AUTOSAR XML (schema 4-0-3)
package /ComponentTypes
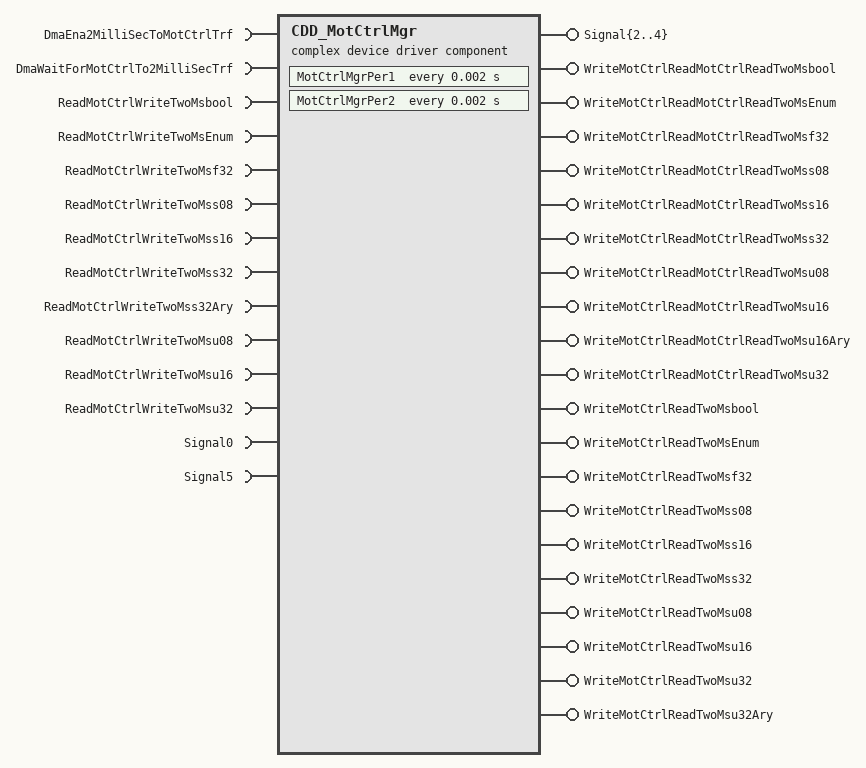
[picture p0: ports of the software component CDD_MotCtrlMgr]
  complex device driver sw component type CDD_MotCtrlMgr
    23 x provide port:
      Signal{2..4}: nonqueued-sender-com-spec{data-element=Val, init-value=-128}, provided-interface=Signal{2..4}
      WriteMotCtrlReadMotCtrlReadTwoMsbool: nonqueued-sender-com-spec{data-element=Logl, init-value=0}, provided-interface=WriteMotCtrlReadMotCtrlReadTwoMsbool
      WriteMotCtrlReadMotCtrlReadTwoMsEnum: nonqueued-sender-com-spec{data-element=Val, init-value=65535}, provided-interface=WriteMotCtrlReadMotCtrlReadTwoMsEnum
      WriteMotCtrlReadMotCtrlReadTwoMsf32: nonqueued-sender-com-spec{data-element=Val, init-value=1.0}, provided-interface=WriteMotCtrlReadMotCtrlReadTwoMsf32
      WriteMotCtrlReadMotCtrlReadTwoMss08: nonqueued-sender-com-spec{data-element=Val, init-value=-128}, provided-interface=WriteMotCtrlReadMotCtrlReadTwoMss08
      WriteMotCtrlReadMotCtrlReadTwoMss16: nonqueued-sender-com-spec{data-element=Val, init-value=-32768}, provided-interface=WriteMotCtrlReadMotCtrlReadTwoMss16
      WriteMotCtrlReadMotCtrlReadTwoMss32: nonqueued-sender-com-spec{data-element=Val, init-value=-2147483647}, provided-interface=WriteMotCtrlReadMotCtrlReadTwoMss32
      WriteMotCtrlReadMotCtrlReadTwoMsu08: nonqueued-sender-com-spec{data-element=Val, init-value=255}, provided-interface=WriteMotCtrlReadMotCtrlReadTwoMsu08
      WriteMotCtrlReadMotCtrlReadTwoMsu16: nonqueued-sender-com-spec{data-element=Val, init-value=65535}, provided-interface=WriteMotCtrlReadMotCtrlReadTwoMsu16
      WriteMotCtrlReadMotCtrlReadTwoMsu16Ary: nonqueued-sender-com-spec{data-element=Ary1D, init-value=[0, 65535]}, provided-interface=WriteMotCtrlReadMotCtrlReadTwoMsu16Ary
      WriteMotCtrlReadMotCtrlReadTwoMsu32: nonqueued-sender-com-spec{data-element=Val, init-value=4294967295}, provided-interface=WriteMotCtrlReadMotCtrlReadTwoMsu32
      WriteMotCtrlReadTwoMsbool: nonqueued-sender-com-spec{data-element=Logl, init-value=1}, provided-interface=WriteMotCtrlReadTwoMsbool
      WriteMotCtrlReadTwoMsEnum: nonqueued-sender-com-spec{data-element=Val, init-value=65535}, provided-interface=WriteMotCtrlReadTwoMsEnum
      WriteMotCtrlReadTwoMsf32: nonqueued-sender-com-spec{data-element=Val, init-value=1.0}, provided-interface=WriteMotCtrlReadTwoMsf32
      WriteMotCtrlReadTwoMss08: nonqueued-sender-com-spec{data-element=Val, init-value=-128}, provided-interface=WriteMotCtrlReadTwoMss08
      WriteMotCtrlReadTwoMss16: nonqueued-sender-com-spec{data-element=Val, init-value=-32768}, provided-interface=WriteMotCtrlReadTwoMss16
      WriteMotCtrlReadTwoMss32: nonqueued-sender-com-spec{data-element=Val, init-value=-2147483647}, provided-interface=WriteMotCtrlReadTwoMss32
      WriteMotCtrlReadTwoMsu08: nonqueued-sender-com-spec{data-element=Val, init-value=255}, provided-interface=WriteMotCtrlReadTwoMsu08
      WriteMotCtrlReadTwoMsu16: nonqueued-sender-com-spec{data-element=Val, init-value=65535}, provided-interface=WriteMotCtrlReadTwoMsu16
      WriteMotCtrlReadTwoMsu32: nonqueued-sender-com-spec{data-element=Val, init-value=4294967295}, provided-interface=WriteMotCtrlReadTwoMsu32
      WriteMotCtrlReadTwoMsu32Ary: nonqueued-sender-com-spec{data-element=Ary1D, init-value=[0, 4294967295]}, provided-interface=WriteMotCtrlReadTwoMsu32Ary
    14 x require port:
      DmaEna2MilliSecToMotCtrlTrf: required-interface=DmaEna2MilliSecToMotCtrlTrf
      DmaWaitForMotCtrlTo2MilliSecTrf: required-interface=DmaWaitForMotCtrlTo2MilliSecTrf
      ReadMotCtrlWriteTwoMsbool: nonqueued-receiver-com-spec{data-element=Logl, filter=data-filter-type=ALWAYS, init-value=0}, required-interface=ReadMotCtrlWriteTwoMsbool
      ReadMotCtrlWriteTwoMsEnum: nonqueued-receiver-com-spec{data-element=Val, filter=data-filter-type=ALWAYS, init-value=4294967295}, required-interface=ReadMotCtrlWriteTwoMsEnum
      ReadMotCtrlWriteTwoMsf32: nonqueued-receiver-com-spec{data-element=Val, filter=data-filter-type=ALWAYS, init-value=1.0}, required-interface=ReadMotCtrlWriteTwoMsf32
      ReadMotCtrlWriteTwoMss08: nonqueued-receiver-com-spec{data-element=Val, filter=data-filter-type=ALWAYS, init-value=-128}, required-interface=ReadMotCtrlWriteTwoMss08
      ReadMotCtrlWriteTwoMss16: nonqueued-receiver-com-spec{data-element=Val, filter=data-filter-type=ALWAYS, init-value=-32768}, required-interface=ReadMotCtrlWriteTwoMss16
      ReadMotCtrlWriteTwoMss32: nonqueued-receiver-com-spec{data-element=Val, filter=data-filter-type=ALWAYS, init-value=-2147483647}, required-interface=ReadMotCtrlWriteTwoMss32
      ReadMotCtrlWriteTwoMss32Ary: nonqueued-receiver-com-spec{data-element=Ary1D, filter=data-filter-type=ALWAYS, init-value=[-2147483647, 2147483647]}, required-interface=ReadMotCtrlWriteTwoMss32Ary
      ReadMotCtrlWriteTwoMsu08: nonqueued-receiver-com-spec{data-element=Val, filter=data-filter-type=ALWAYS, init-value=255}, required-interface=ReadMotCtrlWriteTwoMsu08
      ReadMotCtrlWriteTwoMsu16: nonqueued-receiver-com-spec{data-element=Val, filter=data-filter-type=ALWAYS, init-value=65535}, required-interface=ReadMotCtrlWriteTwoMsu16
      ReadMotCtrlWriteTwoMsu32: nonqueued-receiver-com-spec{data-element=Val, filter=data-filter-type=ALWAYS, init-value=4294967295}, required-interface=ReadMotCtrlWriteTwoMsu32
      Signal0: nonqueued-receiver-com-spec{data-element=Logl, filter=data-filter-type=ALWAYS, init-value=0}, required-interface=Signal0
      Signal5: nonqueued-receiver-com-spec{data-element=Logl, filter=data-filter-type=ALWAYS, init-value=0}, required-interface=Signal5
    behavior CDD_MotCtrlMgr_InternalBehavior
      timing event TMT_MotCtrlMgrPer1: start-on-event=MotCtrlMgrPer1, period=0.002
      timing event TMT_MotCtrlMgrPer2: start-on-event=MotCtrlMgrPer2, period=0.002
      runnable MotCtrlMgrPer1
        data-send-points:
          23 x access:
            SEND_Signal{2..4}_Val: accessed-variable=Signal{2..4}.Val
            SEND_WriteMotCtrlReadMotCtrlReadTwoMsbool_Logl: accessed-variable=WriteMotCtrlReadMotCtrlReadTwoMsbool.Logl
            SEND_WriteMotCtrlReadMotCtrlReadTwoMsEnum_Val: accessed-variable=WriteMotCtrlReadMotCtrlReadTwoMsEnum.Val
            SEND_WriteMotCtrlReadMotCtrlReadTwoMsf32_Val: accessed-variable=WriteMotCtrlReadMotCtrlReadTwoMsf32.Val
            SEND_WriteMotCtrlReadMotCtrlReadTwoMss08_Val: accessed-variable=WriteMotCtrlReadMotCtrlReadTwoMss08.Val
            SEND_WriteMotCtrlReadMotCtrlReadTwoMss16_Val: accessed-variable=WriteMotCtrlReadMotCtrlReadTwoMss16.Val
            SEND_WriteMotCtrlReadMotCtrlReadTwoMss32_Val: accessed-variable=WriteMotCtrlReadMotCtrlReadTwoMss32.Val
            SEND_WriteMotCtrlReadMotCtrlReadTwoMsu08_Val: accessed-variable=WriteMotCtrlReadMotCtrlReadTwoMsu08.Val
            SEND_WriteMotCtrlReadMotCtrlReadTwoMsu16_Val: accessed-variable=WriteMotCtrlReadMotCtrlReadTwoMsu16.Val
            SEND_WriteMotCtrlReadMotCtrlReadTwoMsu16Ary_Ary1D: accessed-variable=WriteMotCtrlReadMotCtrlReadTwoMsu16Ary.Ary1D
            SEND_WriteMotCtrlReadMotCtrlReadTwoMsu32_Val: accessed-variable=WriteMotCtrlReadMotCtrlReadTwoMsu32.Val
            SEND_WriteMotCtrlReadTwoMsbool_Logl: accessed-variable=WriteMotCtrlReadTwoMsbool.Logl
            SEND_WriteMotCtrlReadTwoMsEnum_Val: accessed-variable=WriteMotCtrlReadTwoMsEnum.Val
            SEND_WriteMotCtrlReadTwoMsf32_Val: accessed-variable=WriteMotCtrlReadTwoMsf32.Val
            SEND_WriteMotCtrlReadTwoMss08_Val: accessed-variable=WriteMotCtrlReadTwoMss08.Val
            SEND_WriteMotCtrlReadTwoMss16_Val: accessed-variable=WriteMotCtrlReadTwoMss16.Val
            SEND_WriteMotCtrlReadTwoMss32_Val: accessed-variable=WriteMotCtrlReadTwoMss32.Val
            SEND_WriteMotCtrlReadTwoMsu08_Val: accessed-variable=WriteMotCtrlReadTwoMsu08.Val
            SEND_WriteMotCtrlReadTwoMsu16_Val: accessed-variable=WriteMotCtrlReadTwoMsu16.Val
            SEND_WriteMotCtrlReadTwoMsu32_Val: accessed-variable=WriteMotCtrlReadTwoMsu32.Val
            SEND_WriteMotCtrlReadTwoMsu32Ary_Ary1D: accessed-variable=WriteMotCtrlReadTwoMsu32Ary.Ary1D
        sync call SC_DmaWaitForMotCtrlTo2MilliSecTrf_Oper: operation=DmaWaitForMotCtrlTo2MilliSecTrf.Oper, timeout=0
      runnable MotCtrlMgrPer2
        data-receive-point-by-arguments:
          12 x access:
            REC_ReadMotCtrlWriteTwoMsbool_Logl: accessed-variable=ReadMotCtrlWriteTwoMsbool.Logl
            REC_ReadMotCtrlWriteTwoMsEnum_Val: accessed-variable=ReadMotCtrlWriteTwoMsEnum.Val
            REC_ReadMotCtrlWriteTwoMsf32_Val: accessed-variable=ReadMotCtrlWriteTwoMsf32.Val
            REC_ReadMotCtrlWriteTwoMss08_Val: accessed-variable=ReadMotCtrlWriteTwoMss08.Val
            REC_ReadMotCtrlWriteTwoMss16_Val: accessed-variable=ReadMotCtrlWriteTwoMss16.Val
            REC_ReadMotCtrlWriteTwoMss32_Val: accessed-variable=ReadMotCtrlWriteTwoMss32.Val
            REC_ReadMotCtrlWriteTwoMss32Ary_Ary1D: accessed-variable=ReadMotCtrlWriteTwoMss32Ary.Ary1D
            REC_ReadMotCtrlWriteTwoMsu08_Val: accessed-variable=ReadMotCtrlWriteTwoMsu08.Val
            REC_ReadMotCtrlWriteTwoMsu16_Val: accessed-variable=ReadMotCtrlWriteTwoMsu16.Val
            REC_ReadMotCtrlWriteTwoMsu32_Val: accessed-variable=ReadMotCtrlWriteTwoMsu32.Val
            REC_Signal0_Logl: accessed-variable=Signal0.Logl
            REC_Signal5_Logl: accessed-variable=Signal5.Logl
        sync call SC_DmaEna2MilliSecToMotCtrlTrf_Oper: operation=DmaEna2MilliSecToMotCtrlTrf.Oper, timeout=0
  swc implementation CDD_MotCtrlMgr_Implementation: behavior=CDD_MotCtrlMgr_InternalBehavior
    code-descriptors:
      code Default: artifact-descriptors=autosar-engineering-object={short-label=Default, category=SWSRC}
